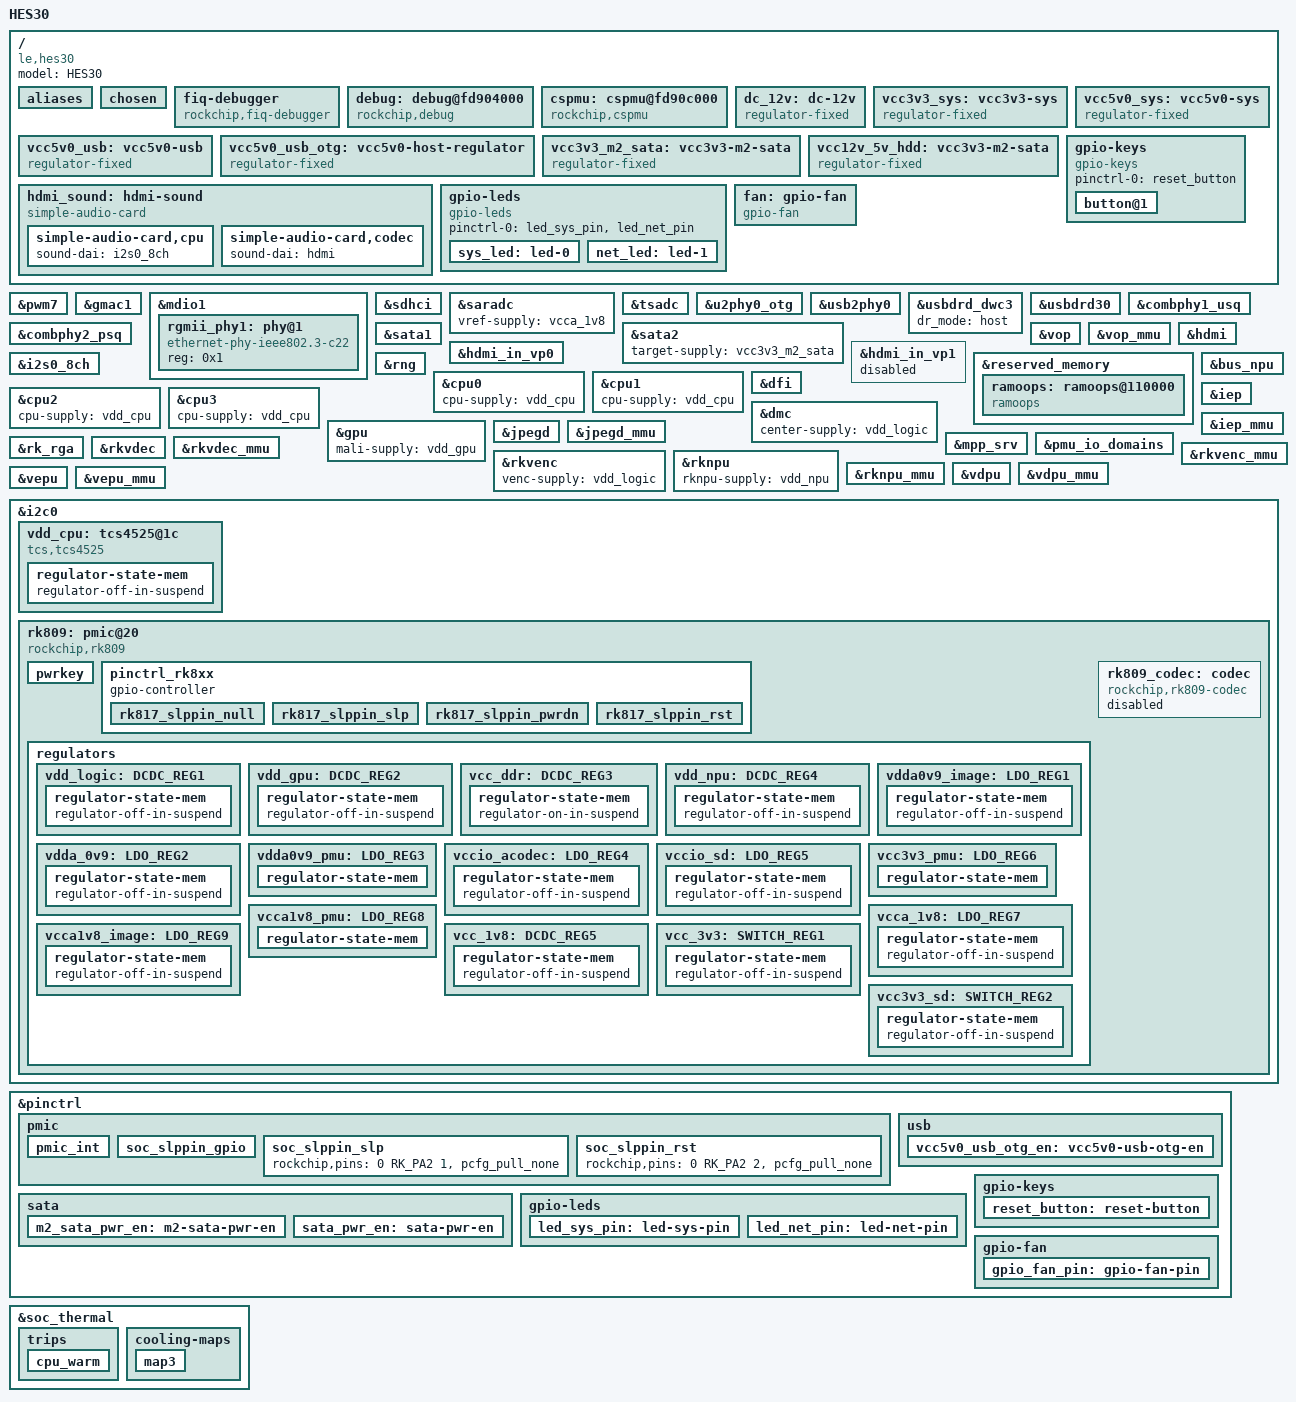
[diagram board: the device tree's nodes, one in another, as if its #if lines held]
/dts-v1/;

#include <dt-bindings/gpio/gpio.h>
#include <dt-bindings/pinctrl/rockchip.h>
#include <dt-bindings/pwm/pwm.h>
#include <dt-bindings/input/rk-input.h>
#include <dt-bindings/sensor-dev.h>
#include "rk3566.dtsi"

/ {
	model = "HES30";
	compatible = "le,hes30", "rockchip,rk3566";

	aliases {
		led-boot = &sys_led;
		led-failsafe = &sys_led;
		led-running = &sys_led;
		led-upgrade = &sys_led;
	};

	chosen: chosen {
		bootargs = "earlycon=uart8250,mmio32,0xfe660000 console=ttyFIQ0 root=PARTUUID=614e0000-0000 rw rootwait";
	};

	fiq-debugger {
		compatible = "rockchip,fiq-debugger";
		rockchip,serial-id = <2>;
		rockchip,wake-irq = <0>;
		/* If enable uart uses irq instead of fiq */
		rockchip,irq-mode-enable = <1>;
		rockchip,baudrate = <1500000>;  /* Only 115200 and 1500000 */
		interrupts = <GIC_SPI 252 IRQ_TYPE_LEVEL_LOW>;
		pinctrl-names = "default";
		pinctrl-0 = <&uart2m0_xfer>;
		status = "okay";
	};

	debug: debug@fd904000 {
		compatible = "rockchip,debug";
		reg = <0x0 0xfd904000 0x0 0x1000>,
			<0x0 0xfd905000 0x0 0x1000>,
			<0x0 0xfd906000 0x0 0x1000>,
			<0x0 0xfd907000 0x0 0x1000>;
	};

	cspmu: cspmu@fd90c000 {
		compatible = "rockchip,cspmu";
		reg = <0x0 0xfd90c000 0x0 0x1000>,
			<0x0 0xfd90d000 0x0 0x1000>,
			<0x0 0xfd90e000 0x0 0x1000>,
			<0x0 0xfd90f000 0x0 0x1000>;
	};

	dc_12v: dc-12v {
		compatible = "regulator-fixed";
		regulator-name = "dc_12v";
		regulator-always-on;
		regulator-boot-on;
		regulator-min-microvolt = <12000000>;
		regulator-max-microvolt = <12000000>;
	};

	vcc3v3_sys: vcc3v3-sys {
		compatible = "regulator-fixed";
		regulator-name = "vcc3v3_sys";
		regulator-always-on;
		regulator-boot-on;
		regulator-min-microvolt = <3300000>;
		regulator-max-microvolt = <3300000>;
		vin-supply = <&dc_12v>;
	};

	vcc5v0_sys: vcc5v0-sys {
		compatible = "regulator-fixed";
		regulator-name = "vcc5v0_sys";
		regulator-always-on;
		regulator-boot-on;
		regulator-min-microvolt = <5000000>;
		regulator-max-microvolt = <5000000>;
		vin-supply = <&dc_12v>;
	};

	vcc5v0_usb: vcc5v0-usb {
		compatible = "regulator-fixed";
		regulator-name = "vcc5v0_usb";
		regulator-always-on;
		regulator-boot-on;
		regulator-min-microvolt = <5000000>;
		regulator-max-microvolt = <5000000>;
		vin-supply = <&dc_12v>;
	};

	vcc5v0_usb_otg: vcc5v0-host-regulator {
		compatible = "regulator-fixed";
		enable-active-high;
		gpio = <&gpio0 RK_PA5 GPIO_ACTIVE_HIGH>;
		pinctrl-names = "default";
		pinctrl-0 = <&vcc5v0_usb_otg_en>;
		regulator-name = "vcc5v0_usb_otg";
		regulator-always-on;
		regulator-min-microvolt = <5000000>;
		regulator-max-microvolt = <5000000>;
		vin-supply = <&vcc5v0_usb>;
	};

	vcc3v3_m2_sata: vcc3v3-m2-sata {
		compatible = "regulator-fixed";
		enable-active-high;
		gpio = <&gpio0 RK_PC4 GPIO_ACTIVE_HIGH>;
		pinctrl-names = "default";
		pinctrl-0 = <&m2_sata_pwr_en>;
		regulator-name = "vcc3v3_m2_sata";
		regulator-min-microvolt = <3300000>;
		regulator-max-microvolt = <3300000>;
		vin-supply = <&vcc5v0_sys>;
	};

	vcc12v_5v_hdd: vcc3v3-m2-sata {
		compatible = "regulator-fixed";
		enable-active-high;
		gpio = <&gpio0 RK_PC1 GPIO_ACTIVE_HIGH>;
		pinctrl-names = "default";
		pinctrl-0 = <&sata_pwr_en>;
		regulator-name = "vcc12v_5v_hdd";
		vin-supply = <&vcc5v0_sys>,<&dc_12v>;
	};

	hdmi_sound: hdmi-sound {
		compatible = "simple-audio-card";
		simple-audio-card,format = "i2s";
		simple-audio-card,mclk-fs = <128>;
		simple-audio-card,name = "rockchip,hdmi";
		status = "disabled";

		simple-audio-card,cpu {
				sound-dai = <&i2s0_8ch>;
		};
		simple-audio-card,codec {
				sound-dai = <&hdmi>;
		};
	};

	gpio-keys {
		compatible = "gpio-keys";
		pinctrl-names = "default";
		pinctrl-0 = <&reset_button>;

		button@1 {
			label = "reset_button";
			linux,code = <KEY_RESTART>;
			gpios = <&gpio0 RK_PC2 GPIO_ACTIVE_LOW>;
			linux,input-type = <1>;
			debounce-interval = <60>;
		};
	};

	gpio-leds {
		compatible = "gpio-leds";
		pinctrl-names = "default";
		pinctrl-0 =
			<&led_sys_pin>,
			<&led_net_pin>;
		sys_led: led-0 {
			label = "red:sys";
			gpios = <&gpio0 RK_PC3 GPIO_ACTIVE_HIGH>;
			linux,default-trigger = "heartbeat";
		};
		net_led: led-1 {
			label = "green:net";
			gpios = <&gpio0 RK_PC7 GPIO_ACTIVE_LOW>;
			default-state = "off";
		};		
	};

#ifdef HES30_FAN_GPIO
	fan: gpio-fan {
		compatible = "gpio-fan";
		pinctrl-names = "default";
		pinctrl-0 = <&gpio_fan_pin>;
		gpios = <&gpio0 RK_PC6 GPIO_ACTIVE_HIGH>;
		#cooling-cells = <2>;
		gpio-fan,speed-map =
			<0 0>,
			<3000 1>;
	};
#else
	fan: pwm-fan {
		compatible = "pwm-fan";
		cooling-levels = <0 0x55 0x66 0x77 0x88 0x99 0xbb 0xcc 0xff>;
		#cooling-cells = <2>;
		fan-supply = <&vcc5v0_sys>;
		// pwms = <&pwm7 0 50000 PWM_POLARITY_INVERTED>;
		pwms = <&pwm7 0 50000 0>;
	};
#endif
};

#ifndef HES30_FAN_GPIO
&pwm7 {
	status = "okay";
};
#endif

&gmac1 {
	snps,reset-gpio = <&gpio4 RK_PC2 GPIO_ACTIVE_LOW>;
	snps,reset-active-low;
	/* Reset time is 20ms, 100ms for rtl8211f */
	snps,reset-delays-us = <0 20000 100000>;

	phy-mode = "rgmii";
	clock_in_out = "output";

	assigned-clocks = <&cru SCLK_GMAC1_RX_TX>, <&cru SCLK_GMAC1>;
	assigned-clock-parents = <&cru SCLK_GMAC1_RGMII_SPEED>, <&cru CLK_MAC1_2TOP>;
	assigned-clock-rates = <0>, <125000000>;

	pinctrl-names = "default";
	pinctrl-0 = <&gmac1m1_miim
			&gmac1m1_tx_bus2
			&gmac1m1_rx_bus2
			&gmac1m1_rgmii_clk
			&gmac1m1_rgmii_bus>;

	tx_delay = <0x35>;
	rx_delay = <0x22>;

	phy-handle = <&rgmii_phy1>;
	status = "okay";
};

&mdio1 {
	rgmii_phy1: phy@1 {
		compatible = "ethernet-phy-ieee802.3-c22";
		reg = <0x1>;
	};
};

// emmc
&sdhci {
	bus-width = <8>;
	supports-emmc;
	non-removable;
	max-frequency = <200000000>;
	status = "okay";
};

&saradc {
	status = "okay";
	vref-supply = <&vcca_1v8>;
};

&tsadc {
	status = "okay";
};

&u2phy0_otg {
	vbus-supply = <&vcc5v0_usb_otg>;
	rockchip,vbus-always-on;
	status = "okay";
};

&usb2phy0 {
	status = "okay";
};

&usbdrd_dwc3 {
	dr_mode = "host";
	status = "okay";
};

&usbdrd30 {
	status = "okay";
};

// sata1
&combphy1_usq {
	status = "okay";
};

// sata2
&combphy2_psq {
	status = "okay";
};

&sata1 {
	// sata1 led
	pinctrl-names = "default";
	pinctrl-0 = <&sata1_pins>;

	target-supply = <&vcc12v_5v_hdd>;
	status = "okay";
};

&sata2 {
	target-supply = <&vcc3v3_m2_sata>;
	status = "okay";
};

// video output

&vop {
	assigned-clocks = <&cru DCLK_VOP0>, <&cru DCLK_VOP1>;
	assigned-clock-parents = <&pmucru PLL_HPLL>, <&cru PLL_VPLL>;
	status = "okay";
};

&vop_mmu {
	status = "okay";
};

&hdmi {
	assigned-clocks = <&cru CLK_HDMI_CEC>;
	assigned-clock-rates = <32768>;
	avdd-0v9-supply = <&vdda0v9_image>;
	avdd-1v8-supply = <&vcca1v8_image>;
	status = "okay";
};

&hdmi_in_vp0 {
	status = "okay";
};

&hdmi_in_vp1 {
	status = "disabled";
};

&hdmi_sound {
	status = "okay";
};

&i2s0_8ch {
	status = "okay";
};

&rng {
	status = "okay";
};

&reserved_memory {
	ramoops: ramoops@110000 {
		compatible = "ramoops";
		reg = <0x0 0x110000 0x0 0xf0000>;
		record-size = <0x20000>;
		console-size = <0x80000>;
		ftrace-size = <0x00000>;
		pmsg-size = <0x50000>;
	};
};

&bus_npu {
	bus-supply = <&vdd_logic>;
	pvtm-supply = <&vdd_cpu>;
	status = "okay";
};

&cpu0 {
	cpu-supply = <&vdd_cpu>;
};

&cpu1 {
	cpu-supply = <&vdd_cpu>;
};

&cpu2 {
	cpu-supply = <&vdd_cpu>;
};

&cpu3 {
	cpu-supply = <&vdd_cpu>;
};

&dfi {
	status = "okay";
};

&dmc {
	center-supply = <&vdd_logic>;
	status = "okay";
};

&gpu {
	mali-supply = <&vdd_gpu>;
	status = "okay";
};

&iep {
	status = "okay";
};

&iep_mmu {
	status = "okay";
};

&jpegd {
	status = "okay";
};

&jpegd_mmu {
	status = "okay";
};

&mpp_srv {
	status = "okay";
};

/*
* There are 10 independent IO domains in RK3566/RK3568, including PMUIO[0:2] and VCCIO[1:7].
* 1/ PMUIO0 and PMUIO1 are fixed-level power domains which cannot be configured;
* 2/ PMUIO2 and VCCIO1,VCCIO[3:7] domains require that their hardware power supply voltages
*    must be consistent with the software configuration correspondingly
*	a/ When the hardware IO level is connected to 1.8V, the software voltage configuration
*	   should also be configured to 1.8V accordingly;
*	b/ When the hardware IO level is connected to 3.3V, the software voltage configuration
*	   should also be configured to 3.3V accordingly;
* 3/ VCCIO2 voltage control selection (0xFDC20140)
*	BIT[0]: 0x0: from GPIO_0A7 (default)
*	BIT[0]: 0x1: from GRF
*    Default is determined by Pin FLASH_VOL_SEL/GPIO0_A7:
*	L:VCCIO2 must supply 3.3V
*	H:VCCIO2 must supply 1.8V
*/
&pmu_io_domains {
	status = "okay";
	pmuio1-supply = <&vcc3v3_pmu>;
	pmuio2-supply = <&vcc3v3_pmu>;
	vccio1-supply = <&vccio_acodec>;
	vccio3-supply = <&vccio_sd>;
	vccio4-supply = <&vcc_3v3>;
	vccio5-supply = <&vcc_1v8>;
	vccio6-supply = <&vcc_1v8>;
	vccio7-supply = <&vcc_3v3>;
};

&rk_rga {
	status = "okay";
};

&rkvdec {
	status = "okay";
};

&rkvdec_mmu {
	status = "okay";
};

&rkvenc {
	venc-supply = <&vdd_logic>;
	status = "okay";
};

&rkvenc_mmu {
	status = "okay";
};

&rknpu {
	rknpu-supply = <&vdd_npu>;
	status = "okay";
};

&rknpu_mmu {
	status = "okay";
};

&vdpu {
	status = "okay";
};

&vdpu_mmu {
	status = "okay";
};

&vepu {
	status = "okay";
};

&vepu_mmu {
	status = "okay";
};

&i2c0 {
	status = "okay";

	vdd_cpu: tcs4525@1c {
		compatible = "tcs,tcs4525";
		reg = <0x1c>;
		vin-supply = <&vcc5v0_sys>;
		regulator-compatible = "fan53555-reg";
		regulator-name = "vdd_cpu";
		regulator-min-microvolt = <712500>;
		regulator-max-microvolt = <1390000>;
		regulator-init-microvolt = <900000>;
		regulator-initial-mode = <1>;
		regulator-ramp-delay = <2300>;
		fcs,suspend-voltage-selector = <1>;
		regulator-boot-on;
		regulator-always-on;
		regulator-state-mem {
			regulator-off-in-suspend;
		};
	};

	rk809: pmic@20 {
		compatible = "rockchip,rk809";
		reg = <0x20>;
		interrupt-parent = <&gpio0>;
		interrupts = <3 IRQ_TYPE_LEVEL_LOW>;

		pinctrl-names = "default", "pmic-sleep",
				"pmic-power-off", "pmic-reset";
		pinctrl-0 = <&pmic_int>;
		pinctrl-1 = <&soc_slppin_slp>, <&rk817_slppin_slp>;
		pinctrl-2 = <&soc_slppin_gpio>, <&rk817_slppin_pwrdn>;
		pinctrl-3 = <&soc_slppin_gpio>, <&rk817_slppin_rst>;

		rockchip,system-power-controller;
		wakeup-source;
		#clock-cells = <1>;
		clock-output-names = "rk808-clkout1", "rk808-clkout2";
		//fb-inner-reg-idxs = <2>;
		/* 1: rst regs (default in codes), 0: rst the pmic */
		pmic-reset-func = <0>;
		/* not save the PMIC_POWER_EN register in uboot */
		not-save-power-en = <1>;

		vcc1-supply = <&vcc3v3_sys>;
		vcc2-supply = <&vcc3v3_sys>;
		vcc3-supply = <&vcc3v3_sys>;
		vcc4-supply = <&vcc3v3_sys>;
		vcc5-supply = <&vcc3v3_sys>;
		vcc6-supply = <&vcc3v3_sys>;
		vcc7-supply = <&vcc3v3_sys>;
		vcc8-supply = <&vcc3v3_sys>;
		vcc9-supply = <&vcc3v3_sys>;

		pwrkey {
			status = "okay";
		};

		pinctrl_rk8xx: pinctrl_rk8xx {
			gpio-controller;
			#gpio-cells = <2>;

			rk817_slppin_null: rk817_slppin_null {
				pins = "gpio_slp";
				function = "pin_fun0";
			};

			rk817_slppin_slp: rk817_slppin_slp {
				pins = "gpio_slp";
				function = "pin_fun1";
			};

			rk817_slppin_pwrdn: rk817_slppin_pwrdn {
				pins = "gpio_slp";
				function = "pin_fun2";
			};

			rk817_slppin_rst: rk817_slppin_rst {
				pins = "gpio_slp";
				function = "pin_fun3";
			};
		};

		regulators {
			vdd_logic: DCDC_REG1 {
				regulator-always-on;
				regulator-boot-on;
				regulator-min-microvolt = <500000>;
				regulator-max-microvolt = <1350000>;
				regulator-init-microvolt = <900000>;
				regulator-ramp-delay = <6001>;
				regulator-initial-mode = <0x2>;
				regulator-name = "vdd_logic";
				regulator-state-mem {
					regulator-off-in-suspend;
				};
			};

			vdd_gpu: DCDC_REG2 {
				regulator-always-on;
				regulator-boot-on;
				regulator-min-microvolt = <500000>;
				regulator-max-microvolt = <1350000>;
				regulator-init-microvolt = <900000>;
				regulator-ramp-delay = <6001>;
				regulator-initial-mode = <0x2>;
				regulator-name = "vdd_gpu";
				regulator-state-mem {
					regulator-off-in-suspend;
				};
			};

			vcc_ddr: DCDC_REG3 {
				regulator-always-on;
				regulator-boot-on;
				regulator-initial-mode = <0x2>;
				regulator-name = "vcc_ddr";
				regulator-state-mem {
					regulator-on-in-suspend;
				};
			};

			vdd_npu: DCDC_REG4 {
				regulator-always-on;
				regulator-boot-on;
				regulator-min-microvolt = <500000>;
				regulator-max-microvolt = <1350000>;
				regulator-init-microvolt = <900000>;
				regulator-ramp-delay = <6001>;
				regulator-initial-mode = <0x2>;
				regulator-name = "vdd_npu";
				regulator-state-mem {
					regulator-off-in-suspend;
				};
			};

			vdda0v9_image: LDO_REG1 {
				regulator-boot-on;
				regulator-always-on;
				regulator-min-microvolt = <900000>;
				regulator-max-microvolt = <900000>;
				regulator-name = "vdda0v9_image";
				regulator-state-mem {
					regulator-off-in-suspend;
				};
			};

			vdda_0v9: LDO_REG2 {
				regulator-always-on;
				regulator-boot-on;
				regulator-min-microvolt = <900000>;
				regulator-max-microvolt = <900000>;
				regulator-name = "vdda_0v9";
				regulator-state-mem {
					regulator-off-in-suspend;
				};
			};

			vdda0v9_pmu: LDO_REG3 {
				regulator-always-on;
				regulator-boot-on;
				regulator-min-microvolt = <900000>;
				regulator-max-microvolt = <900000>;
				regulator-name = "vdda0v9_pmu";
				regulator-state-mem {
					regulator-on-in-suspend;
					regulator-suspend-microvolt = <900000>;
				};
			};

			vccio_acodec: LDO_REG4 {
				regulator-always-on;
				regulator-boot-on;
				regulator-min-microvolt = <3000000>;
				regulator-max-microvolt = <3000000>;
				regulator-name = "vccio_acodec";
				regulator-state-mem {
					regulator-off-in-suspend;
				};
			};

			vccio_sd: LDO_REG5 {
				regulator-always-on;
				regulator-boot-on;
				regulator-min-microvolt = <1800000>;
				regulator-max-microvolt = <3300000>;
				regulator-name = "vccio_sd";
				regulator-state-mem {
					regulator-off-in-suspend;
				};
			};

			vcc3v3_pmu: LDO_REG6 {
				regulator-always-on;
				regulator-boot-on;
				regulator-min-microvolt = <3300000>;
				regulator-max-microvolt = <3300000>;
				regulator-name = "vcc3v3_pmu";
				regulator-state-mem {
					regulator-on-in-suspend;
					regulator-suspend-microvolt = <3300000>;
				};
			};

			vcca_1v8: LDO_REG7 {
				regulator-always-on;
				regulator-boot-on;
				regulator-min-microvolt = <1800000>;
				regulator-max-microvolt = <1800000>;
				regulator-name = "vcca_1v8";
				regulator-state-mem {
					regulator-off-in-suspend;
				};
			};

			vcca1v8_pmu: LDO_REG8 {
				regulator-always-on;
				regulator-boot-on;
				regulator-min-microvolt = <1800000>;
				regulator-max-microvolt = <1800000>;
				regulator-name = "vcca1v8_pmu";
				regulator-state-mem {
					regulator-on-in-suspend;
					regulator-suspend-microvolt = <1800000>;
				};
			};

			vcca1v8_image: LDO_REG9 {
				regulator-always-on;
				regulator-boot-on;
				regulator-min-microvolt = <1800000>;
				regulator-max-microvolt = <1800000>;
				regulator-name = "vcca1v8_image";
				regulator-state-mem {
					regulator-off-in-suspend;
				};
			};

			vcc_1v8: DCDC_REG5 {
				regulator-always-on;
				regulator-boot-on;
				regulator-min-microvolt = <1800000>;
				regulator-max-microvolt = <1800000>;
				regulator-name = "vcc_1v8";
				regulator-state-mem {
					regulator-off-in-suspend;
				};
			};

			vcc_3v3: SWITCH_REG1 {
				regulator-always-on;
				regulator-boot-on;
				regulator-name = "vcc_3v3";
				regulator-state-mem {
					regulator-off-in-suspend;
				};
			};

			vcc3v3_sd: SWITCH_REG2 {
				regulator-always-on;
				regulator-boot-on;
				regulator-name = "vcc3v3_sd";
				regulator-state-mem {
					regulator-off-in-suspend;
				};
			};
		};

		rk809_codec: codec {
			#sound-dai-cells = <1>;
			compatible = "rockchip,rk809-codec", "rockchip,rk817-codec";
			clocks = <&cru I2S1_MCLKOUT>;
			clock-names = "mclk";
			assigned-clocks = <&cru I2S1_MCLKOUT>, <&cru I2S1_MCLK_TX_IOE>;
			assigned-clock-rates = <12288000>;
			assigned-clock-parents = <&cru I2S1_MCLKOUT_TX>, <&cru I2S1_MCLKOUT_TX>;
			pinctrl-names = "default";
			pinctrl-0 = <&i2s1m0_mclk>;
			hp-volume = <20>;
			spk-volume = <3>;
			mic-in-differential;
			status = "disabled";
		};
	};
};

&pinctrl {
	pmic {
		pmic_int: pmic_int {
			rockchip,pins =
				<0 RK_PA3 RK_FUNC_GPIO &pcfg_pull_up>;
		};

		soc_slppin_gpio: soc_slppin_gpio {
			rockchip,pins =
				<0 RK_PA2 RK_FUNC_GPIO &pcfg_output_low>;
		};

		soc_slppin_slp: soc_slppin_slp {
			rockchip,pins =
				<0 RK_PA2 1 &pcfg_pull_none>;
		};

		soc_slppin_rst: soc_slppin_rst {
			rockchip,pins =
				<0 RK_PA2 2 &pcfg_pull_none>;
		};
	};

	usb {
		vcc5v0_usb_otg_en: vcc5v0-usb-otg-en {
			rockchip,pins = <0 RK_PA5 RK_FUNC_GPIO &pcfg_pull_none>;
		};
	};

	sata {
		m2_sata_pwr_en: m2-sata-pwr-en {
			rockchip,pins = <0 RK_PC4 RK_FUNC_GPIO &pcfg_pull_none>;
		};
		sata_pwr_en: sata-pwr-en {
			rockchip,pins = <0 RK_PC1 RK_FUNC_GPIO &pcfg_pull_none>;
		};
	};

	gpio-leds {
		led_sys_pin: led-sys-pin {
			rockchip,pins =
				<0 RK_PC3 RK_FUNC_GPIO &pcfg_pull_none>;
		};
		led_net_pin: led-net-pin {
			rockchip,pins =
				<0 RK_PC7 RK_FUNC_GPIO &pcfg_pull_none>;
		};
	};

	gpio-keys {
		reset_button: reset-button {
			rockchip,pins =
				<0 RK_PC2 RK_FUNC_GPIO &pcfg_pull_none>;
		};
	};

	gpio-fan {
		/omit-if-no-ref/
		gpio_fan_pin: gpio-fan-pin {
			rockchip,pins =
				<0 RK_PC6 RK_FUNC_GPIO &pcfg_pull_none>;
		};
	};
};

#ifdef HES30_FAN_GPIO
&soc_thermal {
	trips {
		cpu_warm: cpu_warm {
			temperature = <65000>;
			hysteresis = <5000>;
			type = "active";
		};
	};

	cooling-maps {

		map3 {
			trip = <&cpu_warm>;
			cooling-device = <&fan 1 1>;
		};

	};
};
#else
&soc_thermal {
	trips {

		cpu_warm: cpu_warm {
			temperature = <65000>;
			hysteresis = <5000>;
			type = "active";
		};

		cpu_hot: cpu_hot {
			temperature = <85000>;
			hysteresis = <5000>;
			type = "active";
		};

		cpu_hall: cpu_hall {
			temperature = <95000>;
			hysteresis = <5000>;
			type = "active";
		};

		cpu_idle: cpu_idle {
			temperature = <47000>;
			hysteresis = <5000>;
			type = "passive";
		};
	};

	cooling-maps {
		map2 {
			trip = <&cpu_idle>;
			cooling-device = <&fan THERMAL_NO_LIMIT 2>;
		};

		map3 {
			trip = <&cpu_warm>;
			cooling-device = <&fan 2 4>;
		};

		map4 {
			trip = <&cpu_hot>;
			cooling-device = <&fan 4 6>;
		};

		map5 {
			trip = <&cpu_hall>;
			cooling-device = <&fan 6 THERMAL_NO_LIMIT>;
		};

	};
};
#endif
